# M55M1 register map
File version: 1.0
Registers are 32-bit, read-write, reset 0x0 unless marked. A register's access mark holds for its fields unless they carry their own. Offsets are from the block's base; [hi:lo] are bit positions; {n}, {i} and the like mark numbered series.

## CLK (part 1 of 2) — CLK Register Map
Base 0x40001000
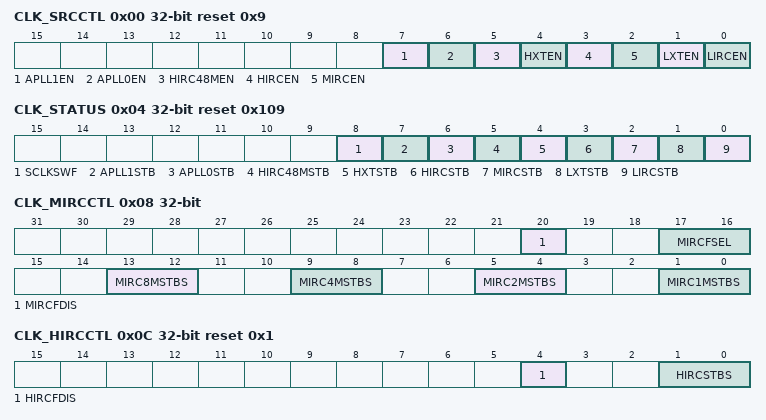
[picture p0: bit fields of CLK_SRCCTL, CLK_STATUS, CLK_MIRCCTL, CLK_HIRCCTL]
0x00 CLK_SRCCTL reset 0x9 — Clock Source Control Register
  [7] APLL1EN — APLL1 Enable Bit (Write Protect). Note 1: This bit is write protected. Refer to the SYS_REGLCTL register. Note 2: This bit is not retained when D2 power is turned off.
    0=APLL1 Disabled; 1=APLL1 Enabled
  [6] APLL0EN — APLL0 Enable Bit (Write Protect). Note 1: This bit is write protected. Refer to the SYS_REGLCTL register. Note 2: This bit is not retained when D2 power is turned off. Note 3: This bit is write ignore when SCLKSEL(CLK_SCLKSEL[2:0]) is set to APLL0.
    0=APLL0 Disabled; 1=APLL0 Enabled
  [5] HIRC48MEN — HIRC48M Enable Bit (Write Protect). Note 1: This bit is write protected. Refer to the SYS_REGLCTL register. Note 2: This bit is not retained when D2 power is turned off. Note 3: This bit is write ignore when SCLKSEL(CLK_SCLKSEL[2:0]) is set to HIRC48M.
    0=48 MHz internal high speed RC oscillator (HIRC48M) Disabled; 1=48 MHz internal high speed RC oscillator (HIRC48M) Enabled
  [4] HXTEN — HXT Enable Bit (Write Protect). Note 1: This bit is write protected. Refer to the SYS_REGLCTL register. Note 2: This bit is not retained when D2 power is turned off. Note 3: This bit is write ignore when SCLKSEL(CLK_SCLKSEL[2:0]) is set to HXT. Note 4: This bit is clear if HXTFIF(CLK_CLKDSTS[5]) is 1.
    0=4~32 MHz external high speed crystal (HXT) Disabled; 1=4~32 MHz external high speed crystal (HXT) Enabled
  [3] HIRCEN — HIRC Enable Bit (Write Protect). Note 1: This bit is write protected. Refer to the SYS_REGLCTL register. Note 2: This bit is not retained when D2 power is turned off. Note 3: This bit is write ignore when SCLKSEL(CLK_SCLKSEL[2:0]) is set to HIRC.
    0=12 MHz internal high speed RC oscillator (HIRC) Disabled; 1=12 MHz internal high speed RC oscillator (HIRC) Enabled
  [2] MIRCEN — MIRC Enable Bit (Write Protect). Note 1: This bit is write protected. Refer to the SYS_REGLCTL register. Note 2: This bit is not retained when D2 power is turned off. Note 3: This bit is write ignore when SCLKSEL(CLK_SCLKSEL[2:0]) is set to MIRC.
    0=1~8 MHz internal middle speed RC oscillator (MIRC) Disabled; 1=1~8 MHz internal middle speed RC oscillator (MIRC) Enabled
  [1] LXTEN wo — LXT Enable Bit (Write Protect) (Write Only). Note 1: This bit is write protected. Refer to the SYS_REGLCTL register. Note 2: This bit is not retained when D5 power is turned off. Note 3: This bit is clear if LXTFIF(CLK_CLKDSTS[13]) is 1.
    0=32.768 kHz external low speed crystal (LXT) Disabled; 1=32.768 kHz external low speed crystal (LXT) Enabled
  [0] LIRCEN — LIRC Enable Bit (Write Protect). Note 1: This bit is write protected. Refer to the SYS_REGLCTL register. Note 2: This bit is not retained when D4 power is turned off.
    0=32 kHz internal low speed RC oscillator (LIRC) Disabled; 1=32 kHz internal low speed RC oscillator (LIRC) Enabled
0x04 CLK_STATUS ro reset 0x109 — Clock Status Monitor Register
  [8] SCLKSWF — System Clock Switching Finish Flag (Read Only). This bit is updated when software switches system clock source. If switch target clock is stable, this bit will be set to 1. If switch target clock is not stable, this bit will be set to 0. Note 1: This bit is read only. After selected clock source is stable, hardware will switch system clock to selected clock automatically, and SCLKSWF will be setted automatically by hardware. Note 2: This bit is not retained when D0 power is turned off.
    0=Clock switching not finish; 1=Clock switching finish
  [7] APLL1STB — Internal APLL1 Clock Source Stable Flag (Read Only). Note: This bit is not retained when D0 power is turned off.
    0=Internal APLL1 clock is not stable or disabled; 1=Internal APLL1 clock is stable and enabled
  [6] APLL0STB — Internal APLL0 Clock Source Stable Flag (Read Only). Note: This bit is not retained when D0 power is turned off.
    0=Internal APLL0 clock is not stable or disabled; 1=Internal APLL0 clock is stable and enabled
  [5] HIRC48MSTB — HIRC48M Clock Source Stable Flag (Read Only). Note: This bit is not retained when D2 power is turned off.
    0=48 MHz internal high speed RC oscillator (HIRC48M) clock is not stable or disabled; 1=48 MHz internal high speed RC oscillator (HIRC48M) clock is stable and enabled
  [4] HXTSTB — HXT Clock Source Stable Flag (Read Only). Note: This bit is not retained when D2 power is turned off.
    0=4~32 MHz external high speed crystal oscillator (HXT) clock is not stable or disabled; 1=4~32 MHz external high speed crystal oscillator (HXT) clock is stable and enabled
  [3] HIRCSTB — HIRC Clock Source Stable Flag (Read Only). Note: This bit is not retained when D2 power is turned off.
    0=12 MHz internal high speed RC oscillator (HIRC) clock is not stable or disabled; 1=12 MHz internal high speed RC oscillator (HIRC) clock is stable and enabled
  [2] MIRCSTB — MIRC Clock Source Stable Flag (Read Only). Note: This bit is not retained when D2 power is turned off.
    0=Internal middle speed RC oscillator (MIRC) clock is not stable or disabled; 1=Internal middle speed RC oscillator (MIRC) clock is stable and enabled
  [1] LXTSTB — LXT Clock Source Stable Flag (Read Only). Note: This bit is not retained when D2 power is turned off.
    0=32.768 kHz external low speed crystal oscillator (LXT) clock is not stable or disabled; 1=32.768 kHz external low speed crystal oscillator (LXT) clock is stabled and enabled
  [0] LIRCSTB — LIRC Clock Source Stable Flag (Read Only). Note: This bit is not retained when D2 power is turned off.
    0=32 kHz internal low speed RC oscillator (LIRC) clock is not stable or disabled; 1=32 kHz internal low speed RC oscillator (LIRC) clock is stable and enabled
0x08 CLK_MIRCCTL — MIRC Control Register
  [20] MIRCFDIS — MIRC Clock Filter Disable Bit. Note 1: This bit is write protected. Refer to the SYS_REGLCTL register. Note 2: This bit is not retained when D2 power is turned off.
    0=MIRC Filter enabled; 1=MIRC Filter disabled
  [17:16] MIRCFSEL — MIRC Frequency Select Bits (Write Protect). Note: These bits are write protected. Refer to the SYS_REGLCTL register. Note 2: These bits are not retained when D2 power is turned off.
    0=Internal middle speed RC oscillator frequency is 1 MHz; 1=Internal middle speed RC oscillator frequency is 2 MHz; 2=Internal middle speed RC oscillator frequency is 4 MHz; 3=Internal middle speed RC oscillator frequency is 8 MHz
  [13:12] MIRC8MSTBS — MIRC8M Stable Count Select (Write Protect). Note 1: These bits are write protected. Refer to the SYS_REGLCTL register. Note 2: These bits are not retained when D2 power is turned off.
    0=MIRC8M stable count is 75 clocks and clock output deviation about 2%; 1=MIRC8M stable count is 56 clocks and clock output deviation about 3%; 2=MIRC8M stable count is 48 clocks and clock output deviation about 4%; 3=MIRC8M stable count is 44 clocks and clock output deviation about 5%
  [9:8] MIRC4MSTBS — MIRC4M Stable Count Select (Write Protect). Note 1: These bits are write protected. Refer to the SYS_REGLCTL register. Note 2: These bits are not retained when D2 power is turned off.
    0=MIRC4M stable count is 20 clocks and clock output deviation about 2%; 1=MIRC4M stable count is 17 clocks and clock output deviation about 3%; 2=MIRC4M stable count is 16 clocks and clock output deviation about 4%; 3=MIRC4M stable count is 14 clocks and clock output deviation about 5%
  [5:4] MIRC2MSTBS — MIRC2M Stable Count Select (Write Protect). Note 1: These bits are write protected. Refer to the SYS_REGLCTL register. Note 2: These bits are not retained when D2 power is turned off.
    0=MIRC2M stable count is 6 clocks and clock output deviation about 2%; 1=MIRC2M stable count is 6 clocks and clock output deviation about 3%; 2=MIRC2M stable count is 5 clocks and clock output deviation about 4%; 3=MIRC2M stable count is 5 clocks and clock output deviation about 5%
  [1:0] MIRC1MSTBS — MIRC1M Stable Count Select (Write Protect). Note 1: These bits are write protected. Refer to the SYS_REGLCTL register. Note 2: These bits are not retained when D2 power is turned off.
    0=MIRC1M stable count is 4 clocks and clock output deviation about 2%; 1=MIRC1M stable count is 4 clocks and clock output deviation about 3%; 2=MIRC1M stable count is 3 clocks and clock output deviation about 4%; 3=MIRC1M stable count is 3 clocks and clock output deviation about 5%
0x0C CLK_HIRCCTL reset 0x1 — HIRC Control Register
  [4] HIRCFDIS — HIRC Clock Filter Disable Bit. Note 1: This bit is write protected. Refer to the SYS_REGLCTL register. Note 2: This bit is not retained when D2 power is turned off.
    0=HIRC Filter enabled; 1=HIRC Filter disabled
  [1:0] HIRCSTBS — HIRC Stable Count Select (Write Protect). Note 1: These bits are write protected. Refer to the SYS_REGLCTL register. Note 2: These bits are not retained when D3 power is turned off.
    0=HIRC stable count is 23 clocks and clock output deviation about 2%; 1=HIRC stable count is 16 clocks and clock output deviation about 3%; 2=HIRC stable count is 14 clocks and clock output deviation about 4%; 3=HIRC stable count is 13 clocks and clock output deviation about 5%
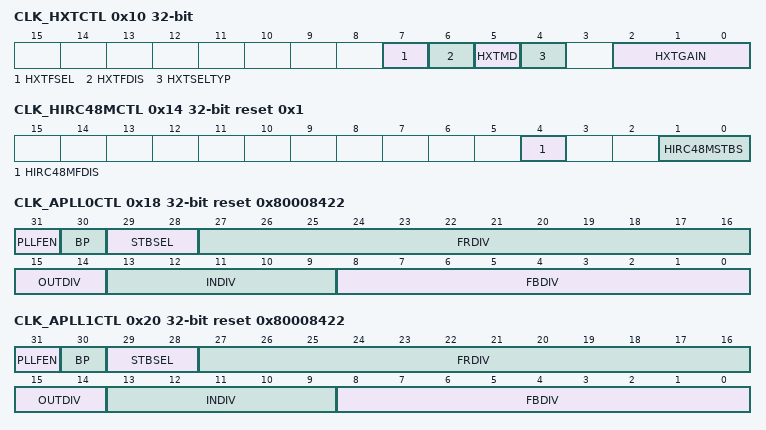
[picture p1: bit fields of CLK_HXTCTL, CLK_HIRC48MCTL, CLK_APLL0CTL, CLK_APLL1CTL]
0x10 CLK_HXTCTL — HXT Control Register
  [7] HXTFSEL — HXT Filter Select (Write Protect). Note 1: This bit is write protected. Refer to the SYS_REGLCTL register. Note 2: This bit is not retained when D2 power is turned off.
    0=HXT frequency is = 32 MHz; 1=HXT frequency is = 4 MHz
  [6] HXTFDIS — HXT Clock Filter Disable Bit (Write Protect). Note 1: This bit is write protected. Refer to the SYS_REGLCTL register. Note 2: This bit is not retained when D2 power is turned off.
    0=HXT Filter enabled; 1=HXT Filter disabled
  [5] HXTMD — HXT Mode Selection (Write Protect). Note 1: This bit is write protected. Refer to the SYS_REGCTL register. Note 2: When external clock mode enable, HXTSELTYP(CLK_HXTCTL[4]) must be set as GM type. Note 3: This bit is not retained when D2 power is turned off.
    0=HXT work as crystal mode. PF.2 and PF.3 are configured as external high speed crystal (HXT) pins; 1=HXT works as external clock mode. PF.3 is configured as external clock input pin
  [4] HXTSELTYP — HXT Crystal Type Select Bit (Write Protect). Note 1: This bit is write protected. Refer to the SYS_REGLCTL register. Note 2: This bit is not retained when D2 power is turned off.
    0=Select INV type; 1=Select GM type
  [2:0] HXTGAIN — HXT Gain Control Bit (Write Protect). The default value is set by Flash controller user configuration register XT1XSG (CONFIG0 [18:16]). Gain control is used to enlarge the gain of crystal to make sure crystal work normally. Note 1: These bits are write protected. Refer to the SYS_REGLCTL register. Note 2: These bits are not retained when D2 power is turned off. Note 3: The default value is set by UCFG0[18:16].
    0=HXT frequency is from 4 MHz to 8 MHz; 1=HXT frequency is from 8 MHz to 12 MHz; 2=HXT frequency is from 12 MHz to 16 MHz; 3=HXT frequency is from 16 MHz to 24 MHz; 4=HXT frequency is from 24 MHz to 32 MHz
0x14 CLK_HIRC48MCTL reset 0x1 — HIRC48M Control Register
  [4] HIRC48MFDIS — HIRC48M Clock Filter Disable Bit. Note 1: This bit is write protected. Refer to the SYS_REGLCTL register. Note 2: This bit is not retained when D2 power is turned off.
    0=HIRC48M Filter enabled; 1=HIRC48M Filter disabled
  [1:0] HIRC48MSTBS — HIRC48M Stable Count Select (Write Protect). Note 1: This bit is write protected. Refer to the SYS_REGLCTL register. Note 2: This bit is not retained when D2 power is turned off.
    0=HIRC48M stable count is 23 clocks and clock output deviation about 2%; 1=HIRC48M stable count is 22 clocks and clock output deviation about 3%; 2=HIRC48M stable count is 21 clocks and clock output deviation about 4%; 3=HIRC48M stable count is 21 clocks and clock output deviation about 5%
0x18 CLK_APLL0CTL reset 0x80008422 — APLL0 Control Register
  [31] PLLFEN — APLL0 Clock Filter Enable Bit. Note 1: This bit is write protected. Refer to the SYS_REGLCTL register. Note 2: This bit is not retained when D2 power is turned off. Note 3: This bit is write ignore when APLL0EN(CLK_SRCCTL[6]) is set to enable.
    0=APLL0 Filter Disable; 1=APLL0 Filter Enable
  [30] BP — APLL0 Bypass Control (Write Protect). Note 1: This bit is write protected. Refer to the SYS_REGLCTL register. Note 2: This bit is not retained when D2 power is turned off. Note 3: This bit is write ignore when APLL0EN(CLK_SRCCTL[6]) is set to enable.
    0=APLL0 is in normal mode (default); 1=APLL0 clock output is same as APLL0 input clock FIN
  [29:28] STBSEL — APLL0 Stable Counter Selection (Write Protect). Note 1: These bits are write protected. Refer to the SYS_REGLCTL register. Note 2: These bits are not retained when D2 power is turned off. Note 3: These bits are write ignore when APLL0EN(CLK_SRCCTL[6]) is set to enable.
    0=APLL0 stable time is 820 APLL0 source clock (source clock is equal to 4M); 1=APLL0 stable time is 2460 APLL0 source clock (4 MHz source clock ≤12 MHz); 2=APLL0 stable time is 4920 APLL0 source clock (12 MHz source clock ≤24 MHz)
  [27:16] FRDIV — APLL0 Fractional Divider Control (Write Protect). Refer to the formulas below the table. Note 1: These bits are write protected. Refer to the SYS_REGLCTL register. Note 2: These bits are not retained when D2 power is turned off. Note 3: These bits are write ignore when APLL0EN(CLK_SRCCTL[6]) is set to enable.
  [15:14] OUTDIV — APLL0 Output Divider Control (Write Protect). Refer to the formulas below the table. Note 1: These bits are write protected. Refer to the SYS_REGLCTL register. Note 2: These bits are not retained when D2 power is turned off. Note 3: These bits are write ignore when APLL0EN(CLK_SRCCTL[6]) is set to enable.
  [13:9] INDIV — APLL0 Input Divider Control (Write Protect). Refer to the formulas below the table. Note 1: These bits are write protected. Refer to the SYS_REGLCTL register. Note 2: These bits are not retained when D2 power is turned off. Note 3: These bits are write ignore when APLL0EN(CLK_SRCCTL[6]) is set to enable.
  [8:0] FBDIV — APLL0 Feedback Divider Control (Write Protect). Refer to the formulas below the table. Note 1: These bits are write protected. Refer to the SYS_REGLCTL register. Note 2: These bits are not retained when D2 power is turned off. Note 3: These bits are write ignore when APLL0EN(CLK_SRCCTL[6]) is set to enable.
0x1C CLK_APLL0SEL — APLL0 Clock Source Select Control Register
  [1:0] APLLSRC — APLL0 Source Clock Selection (Write Protect). Note 1: These bits are write protected. Refer to the SYS_REGLCTL register. Note 2: These bits are not retained when D2 power is turned off. Note 3: These bits are write ignore when APLL0EN(CLK_SRCCTL[6]) is set to enable.
    0=APLL0 source clock from 4~24 MHz external high-speed crystal oscillator (HXT); 1=APLL0 source clock from 24~32 MHz external high-speed crystal oscillator (HXT/2); 2=APLL0 source clock from 12 MHz internal high-speed oscillator (HIRC); 3=APLL0 source clock from 48 MHz internal high-speed oscillator (HIRC48M/4)
0x20 CLK_APLL1CTL reset 0x80008422 — APLL1 Control Register
  [31] PLLFEN — APLL1 Clock Filter Enable Bit. Note 1: This bit is write protected. Refer to the SYS_REGLCTL register. Note 2: This bit is not retained when D2 power is turned off. Note 3: This bit is write ignore when APLL1EN(CLK_SRCCTL[7]) is set to enable.
    0=APLL1 Filter Disable; 1=APLL1 Filter Enable
  [30] BP — APLL1 Bypass Control (Write Protect). Note 1: This bit is write protected. Refer to the SYS_REGLCTL register. Note 2: This bit is not retained when D2 power is turned off. Note 3: This bit is write ignore when APLL1EN(CLK_SRCCTL[7]) is set to enable.
    0=APLL1 is in normal mode (default); 1=APLL1 clock output is same as APLL1 input clock FIN
  [29:28] STBSEL — APLL1 Stable Counter Selection (Write Protect). Note 1: These bits are write protected. Refer to the SYS_REGLCTL register. Note 2: These bits are not retained when D2 power is turned off. Note 3: These bits are write ignore when APLL1EN(CLK_SRCCTL[7]) is set to enable.
    0=APLL1 stable time is 820 APLL1 source clock (source clock is equal to 4M); 1=APLL1 stable time is 2460 APLL1 source clock (4 MHz source clock ≤12 MHz); 2=APLL1 stable time is 4920 APLL1 source clock (12 MHz source clock ≤24 MHz)
  [27:16] FRDIV — APLL1 Fractional Divider Control (Write Protect). Refer to the formulas below the table. Note 1: These bits are write protected. Refer to the SYS_REGLCTL register. Note 2: These bits are not retained when D2 power is turned off. Note 3: These bits are write ignore when APLL1EN(CLK_SRCCTL[7]) is set to enable.
  [15:14] OUTDIV — APLL1 Output Divider Control (Write Protect). Refer to the formulas below the table. Note 1: These bits are write protected. Refer to the SYS_REGLCTL register. Note 2: These bits are not retained when D2 power is turned off. Note 3: These bits are write ignore when APLL1EN(CLK_SRCCTL[7]) is set to enable.
  [13:9] INDIV — APLL1 Input Divider Control (Write Protect). Refer to the formulas below the table. Note 1: These bits are write protected. Refer to the SYS_REGLCTL register. Note 2: These bits are not retained when D2 power is turned off. Note 3: These bits are write ignore when APLL1EN(CLK_SRCCTL[7]) is set to enable.
  [8:0] FBDIV — APLL1 Feedback Divider Control (Write Protect). Refer to the formulas below the table. Note 1: These bits are write protected. Refer to the SYS_REGLCTL register. Note 2: These bits are not retained when D2 power is turned off. Note 3: These bits are write ignore when APLL1EN(CLK_SRCCTL[7]) is set to enable.
0x24 CLK_APLL1SEL — APLL1 Clock Source Select Control Register
  [1:0] APLLSRC — APLL1 Source Clock Selection (Write Protect). Note 1: These bits are write protected. Refer to the SYS_REGLCTL register. Note 2: These bits are not retained when D2 power is turned off. Note 3: These bits are write ignore when APLL1EN(CLK_SRCCTL[7]) is set to enable.
    0=APLL1 source clock from 4~24 MHz external high-speed crystal oscillator (HXT); 1=APLL1 source clock from 24~32 MHz external high-speed crystal oscillator (HXT/2); 2=APLL1 source clock from 12 MHz internal high-speed oscillator (HIRC); 3=APLL1 source clock from 48 MHz internal high-speed oscillator (HIRC48M/4)
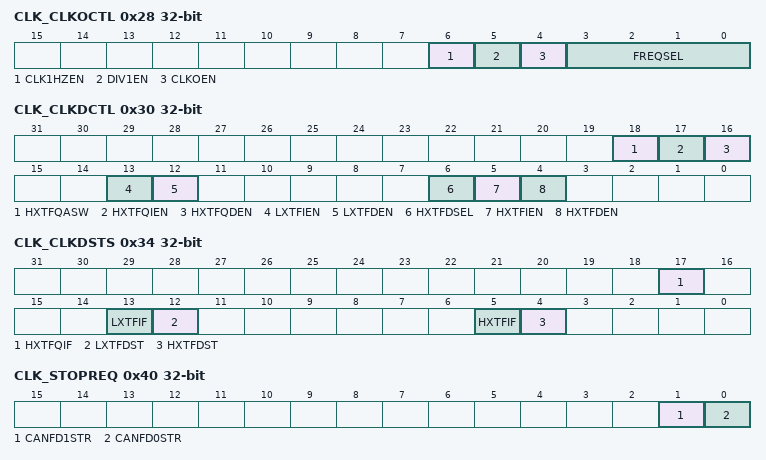
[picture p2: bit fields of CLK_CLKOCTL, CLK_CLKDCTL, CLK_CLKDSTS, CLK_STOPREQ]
0x28 CLK_CLKOCTL — Clock Output Control Register
  [6] CLK1HZEN — Clock Output 1Hz Enable Bit. Note: This bit is not retained when D2 power is turned off.
    0=1 Hz clock output for 32.768 kHz frequency compensation Disabled; 1=1 Hz clock output for 32.768 kHz frequency compensation Enabled
  [5] DIV1EN — Clock Output Divide One Enable Bit. Note: This bit is not retained when D2 power is turned off.
    0=Clock Output will output clock with source frequency divided by FREQSEL; 1=Clock Output will output clock with source frequency
  [4] CLKOEN — Clock Output Enable Bit. Note: This bit is not retained when D2 power is turned off.
    0=Clock Output function Disabled; 1=Clock Output function Enabled
  [3:0] FREQSEL — Clock Output Frequency Selection. The formula of output frequency is. Fin is the input clock frequency. Fout is the frequency of divider output clock. N is the 4-bit value of FREQSEL[3:0]. Note: These bits are not retained when D2 power is turned off.
0x30 CLK_CLKDCTL — Clock Fail Detector Control Register
  [18] HXTFQASW — HXT Clock Frequency Range Detector Event Auto Switch Enable Bit. Note 1: This bit should be set before HXTFQDEN(CLK_CLKDCTL[16]). Note 2: This bit is not retained when D2 power is turned off.
    0=4~32 MHz external high speed crystal oscillator (HXT) clock frequency range detector fail event happened and SCLK will not switch to HIRC automatically; 1=4~32 MHz external high speed crystal oscillator (HXT) clock frequency range detector fail event happened and SCLK will switch to HIRC automatically
  [17] HXTFQIEN — HXT Clock Frequency Range Detector Interrupt Enable Bit. Note: This bit is not retained when D2 power is turned off.
    0=4~32 MHz external high speed crystal oscillator (HXT) clock frequency range detector fail interrupt Disabled; 1=4~32 MHz external high speed crystal oscillator (HXT) clock frequency range detector fail interrupt Enabled
  [16] HXTFQDEN — HXT Clock Frequency Range Detector Enable Bit. Note: This bit is not retained when D2 power is turned off.
    0=4~32 MHz external high speed crystal oscillator (HXT) clock frequency range detector Disabled; 1=4~32 MHz external high speed crystal oscillator (HXT) clock frequency range detector Enabled
  [13] LXTFIEN — LXT Clock Fail Interrupt Enable Bit. Note: This bit is not retained when D2 power is turned off.
    0=32.768 kHz external low speed crystal oscillator (LXT) clock fail interrupt Disabled; 1=32.768 kHz external low speed crystal oscillator (LXT) clock fail interrupt Enabled
  [12] LXTFDEN — LXT Clock Fail Detector Enable Bit. Note: This bit is not retained when D2 power is turned off.
    0=32.768 kHz external low speed crystal oscillator (LXT) clock fail detector Disabled; 1=32.768 kHz external low speed crystal oscillator (LXT) clock fail detector Enabled
  [6] HXTFDSEL — HXT Clock Fail Detector Selection. Note 1: When HXT Clock Fail Detector Selection is set, detector will keep detect whether HXT is stable or not, prevent HXT fail before stable. Note 2: This bit is not retained when D2 power is turned off.
    0=4~32 MHz external high speed crystal oscillator (HXT) clock fail detector after HXT stable; 1=4~32 MHz external high speed crystal oscillator (HXT) clock fail detector bypass HXT stable
  [5] HXTFIEN — HXT Clock Fail Interrupt Enable Bit. Note: This bit is not retained when D2 power is turned off.
    0=4~32 MHz external high speed crystal oscillator (HXT) clock fail interrupt Disabled; 1=4~32 MHz external high speed crystal oscillator (HXT) clock fail interrupt Enabled
  [4] HXTFDEN — HXT Clock Fail Detector Enable Bit. Note: This bit is not retained when D2 power is turned off.
    0=4~32 MHz external high speed crystal oscillator (HXT) clock fail detector Disabled; 1=4~32 MHz external high speed crystal oscillator (HXT) clock fail detector Enabled
0x34 CLK_CLKDSTS — Clock Fail Detector Status Register
  [17] HXTFQIF — HXT Clock Frequency Range Detector Interrupt Flag (Write Protect). Note 1: Write 1 to clear this bit to 0. Note 2: This bit is write protected. Refer to the SYS_REGLCTL register. Note 3: This bit is not retained when D2 power is turned off.
    0=4~32 MHz external high speed crystal oscillator (HXT) clock frequency is normal; 1=4~32 MHz external high speed crystal oscillator (HXT) clock frequency is abnormal
  [13] LXTFIF — LXT Clock Fail Interrupt Flag (Write Protect). Note 1: Write 1 to clear this bit to 0. Note 2: This bit is write protected. Refer to the SYS_REGLCTL register. Note 3: This bit is not retained when D2 power is turned off.
    0=32.768 kHz external low speed crystal oscillator (LXT) clock is normal; 1=32.768 kHz external low speed crystal oscillator (LXT) stops
  [12] LXTFDST — LXT Clock Fail Detector Status Bit. Note: This bit is not retained when D0 power is turned off.
    0=Indicate 32.768 kHz external low speed crystal oscillator (LXT) clock fail detector already disabled; 1=Indicate 32.768 kHz external low speed crystal oscillator (LXT) clock fail detector already enabled
  [5] HXTFIF — HXT Clock Fail Interrupt Flag (Write Protect). Note 1: Write 1 to clear this bit to 0. Note 2: This bit is write protected. Refer to the SYS_REGLCTL register. Note 3: This bit is not retained when D2 power is turned off.
    0=4~32 MHz external high speed crystal oscillator (HXT) clock is normal; 1=4~32 MHz external high speed crystal oscillator (HXT) clock stops
  [4] HXTFDST — HXT Clock Fail Detector Status Bit. Note: This bit is not retained when D0 power is turned off.
    0=Indicate 4~32 MHz external high speed crystal oscillator (HXT) clock fail detector already disabled; 1=Indicate 4~32 MHz external high speed crystal oscillator (HXT) clock fail detector already enabled
0x38 CLK_CDUPB — Clock Frequency Range Detector Upper Boundary Register
  [9:0] UPERBD — HXT Clock Frequency Range Detector Upper Boundary Value. The bits define the high value of frequency monitor window. When HXT frequency monitor value higher than this register, the HXT frequency detect fail interrupt flag will set to 1. Frequency out of range will be asserted when HXT frequency ((UPERBD+1)/512)* HIRC48M frequency. Note: These bits are not retained when D2 power is turned off.
0x3C CLK_CDLOWB — Clock Frequency Range Detector Lower Boundary Register
  [9:0] LOWERBD — HXT Clock Frequency Range Detector Lower Boundary Value. The bits define the low value of frequency monitor window. When HXT frequency monitor value lower than this register, the HXT frequency detect fail interrupt flag will set to 1. Frequency out of range will be asserted when HXT frequency ((LOWERBD+1)/512)* HIRC48M frequency. Note: These bits are not retained when D2 power is turned off.
0x40 CLK_STOPREQ — Clock Stop Request Register
  [1] CANFD1STR — CANFD1 Clock Stop Request. This bit is used to stop CANFD1 clock. Note: This bit is not retained when D1 power is turned off.
    0=CANFD1 clock is not stopped by this bit. (default); 1=Set this bit and check the CANFD1STA(CLK_STOPACK[1]) is 1, then CANFD1 clock stop
  [0] CANFD0STR — CANFD0 Clock Stop Request. This bit is used to stop CANFD0 clock. Note: This bit is not retained when D1 power is turned off.
    0=CANFD0 clock is not stopped by this bit. (default); 1=Set this bit and check the CANFD0STA(CLK_STOPACK[0]) is 1, then CANFD0 clock stop
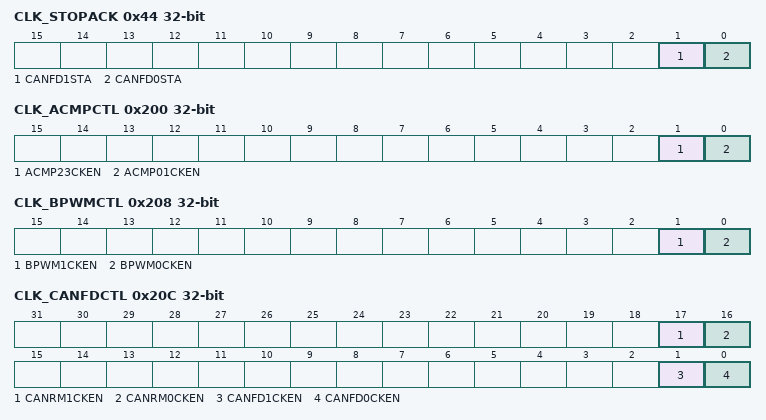
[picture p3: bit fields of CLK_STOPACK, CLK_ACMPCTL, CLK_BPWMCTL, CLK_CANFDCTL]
0x44 CLK_STOPACK ro — Clock Stop Acknowledge Register
  [1] CANFD1STA — CANFD1 Clock Stop Acknowledge (Read Only). This bit is used to check CANFD1 clock stop by setting CANFD1STR(CLK_STOPREQ[1]). Note: This bit is not retained when D1 power is turned off.
    0=CANFD1 clock not stopped; 1=CANFD1 clock stopped
  [0] CANFD0STA — CANFD0 Clock Stop Acknowledge (Read Only). This bit is used to check CANFD0 clock stop by setting CANFD0STR(CLK_STOPREQ[0]). Note: This bit is not retained when D1 power is turned off.
    0=CANFD0 clock not stopped; 1=CANFD0 clock stopped
0x200 CLK_ACMPCTL — ACMP Clock Enable Control Register
  [1] ACMP23CKEN — ACMP2/3 Clock Enable Bit. Note: This bit is not retained when D0 power is turned off.
    0=ACMP2/3 clock Disabled; 1=ACMP2/3 clock Enabled
  [0] ACMP01CKEN — ACMP0/1 Clock Enable Bit. Note: This bit is not retained when D0 power is turned off.
    0=ACMP0/1 clock Disabled; 1=ACMP0/1 clock Enabled
0x204 CLK_AWFCTL — AWF Clock Enable Control Register
  [0] AWF0CKEN — AWFx Clock Enable Bit. Note: This bit is not retained when D0 power is turned off.
    0=AWFx clock Disabled; 1=AWFx clock Enabled
0x208 CLK_BPWMCTL — BPWM Clock Enable Control Register
  [1] BPWM1CKEN — BPWMx Clock Enable Bit. Note: This bit is not retained when D0 power is turned off.
    0=BPWMx clock Disabled; 1=BPWMx clock Enabled
  [0] BPWM0CKEN — BPWMx Clock Enable Bit. Note: This bit is not retained when D0 power is turned off.
    0=BPWMx clock Disabled; 1=BPWMx clock Enabled
0x20C CLK_CANFDCTL — CANFD Clock Enable Control Register
  [17] CANRM1CKEN — CANFD1 Message SRAM Clock Enable Bit. Note: This bit is not retained when D0 power is turned off.
    0=CANFD1 Message SRAM clock Disabled; 1=CANFD1 Message SRAM clock Enabled
  [16] CANRM0CKEN — CANFD0 Message SRAM Clock Enable Bit. Note: This bit is not retained when D0 power is turned off.
    0=CANFD0 Message SRAM clock Disabled; 1=CANFD0 Message SRAM clock Enabled
  [1] CANFD1CKEN — CANFDx Clock Enable Bit. Note: This bit is not retained when D0 power is turned off.
    0=CANFDx clock Disabled; 1=CANFDx clock Enabled
  [0] CANFD0CKEN — CANFDx Clock Enable Bit. Note: This bit is not retained when D0 power is turned off.
    0=CANFDx clock Disabled; 1=CANFDx clock Enabled
0x210 CLK_CCAPCTL — CCAP Clock Enable Control Register
  [0] CCAP0CKEN — CCAPx Clock Enable Bit. Note: This bit is not retained when D0 power is turned off.
    0=CCAPx clock Disabled; 1=CCAPx clock Enabled
0x214 CLK_CRCCTL — CRC Clock Enable Control Register
  [0] CRC0CKEN — CRCx Clock Enable Bit. Note: This bit is not retained when D0 power is turned off.
    0=CRCx clock Disabled; 1=CRCx clock Enabled
0x218 CLK_CRYPTOCTL — CRYPTO Clock Enable Control Register
  [0] CRYPTO0CKEN — CRYPTOx Clock Enable Bit. Note: This bit is not retained when D0 power is turned off.
    0=CRYPTOx clock Disabled; 1=CRYPTOx clock Enabled
0x21C CLK_DACCTL — DAC Clock Enable Control Register
  [0] DAC01CKEN — DAC0/DAC1 Clock Enable Bit. Note: This bit is not retained when D0 power is turned off.
    0=DAC0/1 clock Disabled; 1=DAC0/1 clock Enabled
0x220 CLK_DMICCTL — DMIC Clock Enable Control Register
  [0] DMIC0CKEN — DMICx Clock Enable Bit. Note: This bit is not retained when D2 power is turned off.
    0=DMICx clock Disabled; 1=DMICx clock Enabled
0x224 CLK_EADCCTL — EADC Clock Enable Control Register
  [0] EADC0CKEN — EADCx Clock Enable Bit. Note: This bit is not retained when D0 power is turned off.
    0=EADCx clock Disabled; 1=EADCx clock Enabled
0x228 CLK_EBICTL — EBI Clock Enable Control Register
  [0] EBI0CKEN — EBIx Clock Enable Bit. Note: This bit is not retained when D0 power is turned off.
    0=EBIx clock Disabled; 1=EBIx clock Enabled
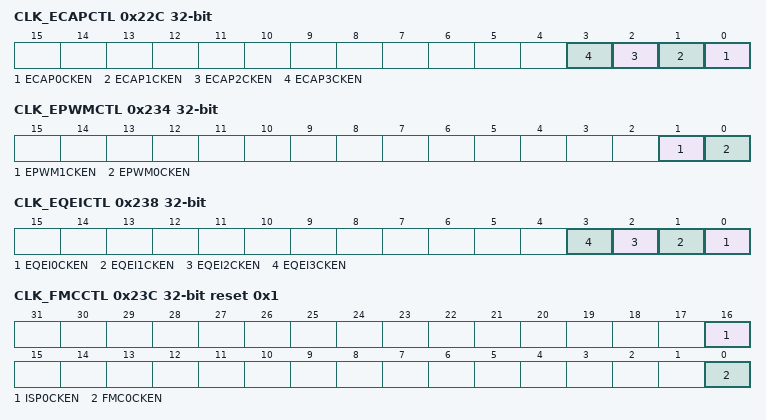
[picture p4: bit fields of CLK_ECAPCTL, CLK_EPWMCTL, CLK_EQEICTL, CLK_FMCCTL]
0x22C CLK_ECAPCTL — ECAP Clock Enable Control Register
  [all] fields
    0=ECAPx clock Disabled; 1=ECAPx clock Enabled
  [n] ECAP{n}CKEN (n=0..3) — ECAPx Clock Enable Bit. Note: This bit is not retained when D0 power is turned off.
0x230 CLK_EMACCTL — EMAC Clock Enable Control Register
  [0] EMAC0CKEN — EMACx Clock Enable Bit. Note: This bit is not retained when D0 power is turned off.
    0=EMACx clock Disabled; 1=EMACx clock Enabled
0x234 CLK_EPWMCTL — EPWM Clock Enable Control Register
  [1] EPWM1CKEN — EPWMx Clock Enable Bit. Note: This bit is not retained when D0 power is turned off.
    0=EPWMx clock Disabled; 1=EPWMx clock Enabled
  [0] EPWM0CKEN — EPWMx Clock Enable Bit. Note: This bit is not retained when D0 power is turned off.
    0=EPWMx clock Disabled; 1=EPWMx clock Enabled
0x238 CLK_EQEICTL — EQEI Clock Enable Control Register
  [all] fields
    0=EQEIx clock Disabled; 1=EQEIx clock Enabled
  [n] EQEI{n}CKEN (n=0..3) — EQEIx Clock Enable Bit. Note: This bit is not retained when D0 power is turned off.
0x23C CLK_FMCCTL reset 0x1 — FMC Clock Enable Control Register
  [16] ISP0CKEN — ISPx Clock Enable Bit. Note: This bit is not retained when D0 power is turned off.
    0=ISPx clock Disabled; 1=ISPx clock Enabled
  [0] FMC0CKEN — FMCx Clock Enable Bit. Note: This bit is not retained when D0 power is turned off.
    0=FMC clock Disabled when chip is under IDLE mode; 1=FMC clock Enabled when chip is under IDLE mode
0x240 CLK_GDMACTL — GDMA Clock Enable Control Register
  [0] GDMA0CKEN — GDMAx Clock Enable Bit. Note: This bit is not retained when D0 power is turned off.
    0=GDMAx clock Disabled; 1=GDMAx clock Enabled
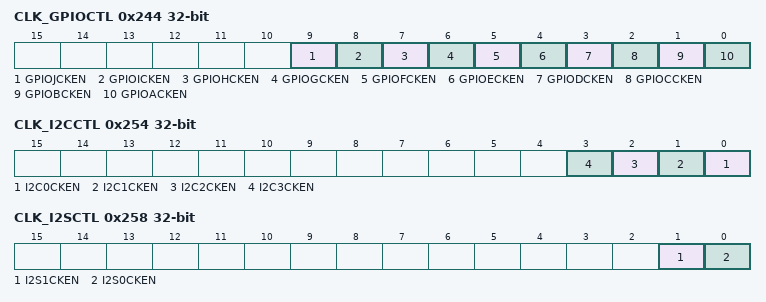
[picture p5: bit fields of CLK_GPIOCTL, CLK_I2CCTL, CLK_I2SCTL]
0x244 CLK_GPIOCTL — GPIO Clock Enable Control Register
  [9] GPIOJCKEN — GPIOJ Clock Enable Bit. Note: This bit is not retained when D0 power is turned off.
    0=GPIOJ clock Disabled; 1=GPIOJ clock Enabled
  [8] GPIOICKEN — GPIOI Clock Enable Bit. Note: This bit is not retained when D0 power is turned off.
    0=GPIOI clock Disabled; 1=GPIOI clock Enabled
  [7] GPIOHCKEN — GPIOH Clock Enable Bit. Note: This bit is not retained when D0 power is turned off.
    0=GPIOH clock Disabled; 1=GPIOH clock Enabled
  [6] GPIOGCKEN — GPIOG Clock Enable Bit. Note: This bit is not retained when D0 power is turned off.
    0=GPIOG clock Disabled; 1=GPIOG clock Enabled
  [5] GPIOFCKEN — GPIOF Clock Enable Bit. Note: This bit is not retained when D0 power is turned off.
    0=GPIOF clock Disabled; 1=GPIOF clock Enabled
  [4] GPIOECKEN — GPIOE Clock Enable Bit. Note: This bit is not retained when D0 power is turned off.
    0=GPIOE clock Disabled; 1=GPIOE clock Enabled
  [3] GPIODCKEN — GPIOD Clock Enable Bit. Note: This bit is not retained when D0 power is turned off.
    0=GPIOD clock Disabled; 1=GPIOD clock Enabled
  [2] GPIOCCKEN — GPIOC Clock Enable Bit. Note: This bit is not retained when D0 power is turned off.
    0=GPIOC clock Disabled; 1=GPIOC clock Enabled
  [1] GPIOBCKEN — GPIOB Clock Enable Bit. Note: This bit is not retained when D0 power is turned off.
    0=GPIOB clock Disabled; 1=GPIOB clock Enabled
  [0] GPIOACKEN — GPIOA Clock Enable Bit. Note: This bit is not retained when D0 power is turned off.
    0=GPIOA clock Disabled; 1=GPIOA clock Enabled
0x248 CLK_HSOTGCTL — HSOTG Clock Enable Control Register
  [0] HSOTG0CKEN — HSOTGx Clock Enable Bit. Note: This bit is not retained when D0 power is turned off.
    0=HSOTGx clock Disabled; 1=HSOTGx clock Enabled
0x24C CLK_HSUSBDCTL — HSUSBD Clock Enable Control Register
  [0] HSUSBD0CKEN — HSUSBDx Clock Enable Bit. Note: This bit is not retained when D0 power is turned off.
    0=HSUSBDx clock Disabled; 1=HSUSBDx clock Enabled
0x250 CLK_HSUSBHCTL — HSUSBH Clock Enable Control Register
  [0] HSUSBH0CKEN — HSUSBHx Clock Enable Bit. Note: This bit is not retained when D0 power is turned off.
    0=HSUSBHx clock Disabled; 1=HSUSBHx clock Enabled
0x254 CLK_I2CCTL — I2C Clock Enable Control Register
  [all] fields
    0=I2Cx clock Disabled; 1=I2Cx clock Enabled
  [n] I2C{n}CKEN (n=0..3) — I2Cx Clock Enable Bit. Note: This bit is not retained when D0 power is turned off.
0x258 CLK_I2SCTL — I2S Clock Enable Control Register
  [1] I2S1CKEN — I2Sx Clock Enable Bit. Note: This bit is not retained when D0 power is turned off.
    0=I2Sx clock Disabled; 1=I2Sx clock Enabled
  [0] I2S0CKEN — I2Sx Clock Enable Bit. Note: This bit is not retained when D0 power is turned off.
    0=I2Sx clock Disabled; 1=I2Sx clock Enabled
